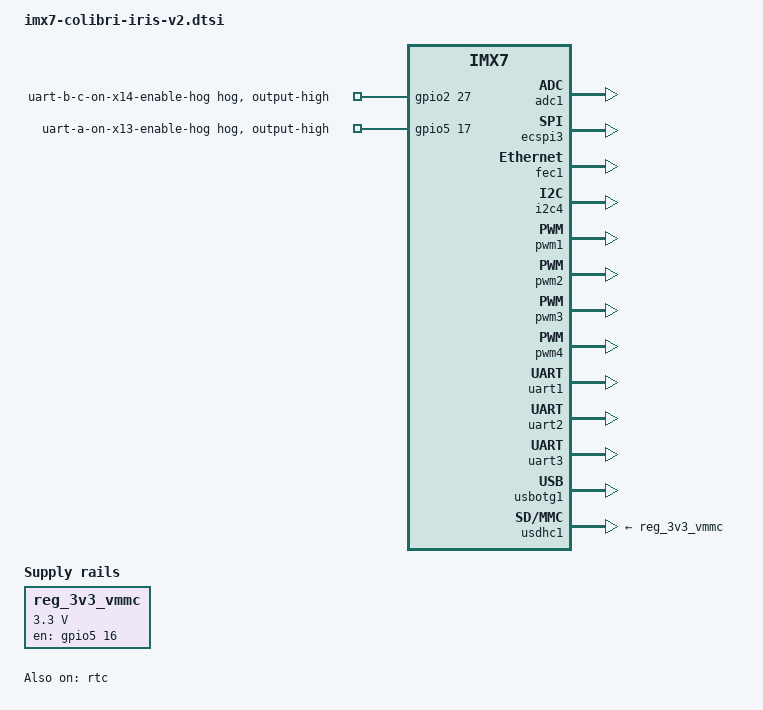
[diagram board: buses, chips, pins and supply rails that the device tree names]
/ {
	reg_3v3_vmmc: regulator-3v3-vmmc {
		compatible = "regulator-fixed";
		enable-active-high;
		gpio = <&gpio5 16 GPIO_ACTIVE_HIGH>;  
		regulator-max-microvolt = <3300000>;
		regulator-min-microvolt = <3300000>;
		regulator-name = "3v3_vmmc";
		startup-delay-us = <100>;
	};
};
&adc1 {
	status = "okay";
};
&ecspi3 {
	status = "okay";
};
&fec1 {
	status = "okay";
};
&gpio2 {
	uart-b-c-on-x14-enable-hog {
		gpio-hog;
		gpios = <27 GPIO_ACTIVE_HIGH>;  
		output-high;
	};
};
&gpio5 {
	uart-a-on-x13-enable-hog {
		gpio-hog;
		gpios = <17 GPIO_ACTIVE_HIGH>;  
		output-high;
	};
};
&i2c4 {
	status = "okay";
};
&pwm1 {
	status = "okay";
};
&pwm2 {
	status = "okay";
};
&pwm3 {
	status = "okay";
};
&pwm4 {
	status = "okay";
};
&rtc {
	status = "okay";
};
&uart1 {
	status = "okay";
};
&uart2 {
	status = "okay";
};
&uart3 {
	status = "okay";
};
&usbotg1 {
	disable-over-current;
	status = "okay";
};
&usdhc1 {
	cap-power-off-card;
	/delete-property/ keep-power-in-suspend;
	/delete-property/ no-1-8-v;
	vmmc-supply = <&reg_3v3_vmmc>;
	status = "okay";
};
